# STM32L4x6_v1r1 register map
File version: 1.1
CPU: CM4 r0p1, little endian, MPU, FPU, 4 interrupt priority bits
Registers are 32-bit, read-write, reset 0x0 unless marked. A register's access mark holds for its fields unless they carry their own. Offsets are from the block's base; [hi:lo] are bit positions; {n}, {i} and the like mark numbered series.

## ADC_Common — Analog-to-Digital Converter
Base 0x50040300
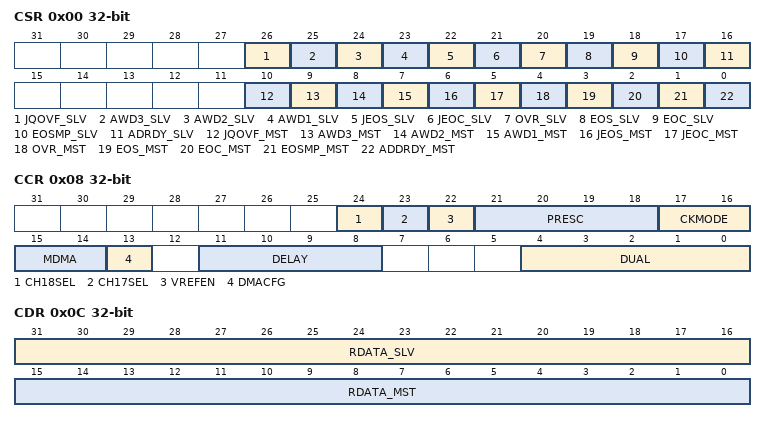
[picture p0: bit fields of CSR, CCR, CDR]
0x00 CSR ro — ADC Common status register
  [26] JQOVF_SLV — Injected Context Queue Overflow flag of the slave ADC
  [25] AWD3_SLV — Analog watchdog 3 flag of the slave ADC
  [24] AWD2_SLV — Analog watchdog 2 flag of the slave ADC
  [23] AWD1_SLV — Analog watchdog 1 flag of the slave ADC
  [22] JEOS_SLV — End of injected sequence flag of the slave ADC
  [21] JEOC_SLV — End of injected conversion flag of the slave ADC
  [20] OVR_SLV — Overrun flag of the slave ADC
  [19] EOS_SLV — End of regular sequence flag of the slave ADC
  [18] EOC_SLV — End of regular conversion of the slave ADC
  [17] EOSMP_SLV
  [16] ADRDY_SLV
  [10] JQOVF_MST
  [9] AWD3_MST
  [8] AWD2_MST
  [7] AWD1_MST
  [6] JEOS_MST
  [5] JEOC_MST
  [4] OVR_MST
  [3] EOS_MST
  [2] EOC_MST
  [1] EOSMP_MST
  [0] ADDRDY_MST
0x08 CCR — ADC common control register
  [24] CH18SEL — CH18 selection
  [23] CH17SEL — CH17 selection
  [22] VREFEN — VREFINT enable
  [21:18] PRESC — ADC prescaler
  [17:16] CKMODE — ADC clock mode
  [15:14] MDMA — Direct memory access mode for multi ADC mode
  [13] DMACFG — DMA configuration (for multi-ADC mode)
  [11:8] DELAY — Delay between 2 sampling phases
  [4:0] DUAL — Dual ADC mode selection
0x0C CDR ro — ADC common regular data register for dual and triple modes
  [31:16] RDATA_SLV — Regular data of the slave ADC
  [15:0] RDATA_MST — Regular data of the master ADC

## GPIOA — General-purpose I/Os
Base 0x48000000
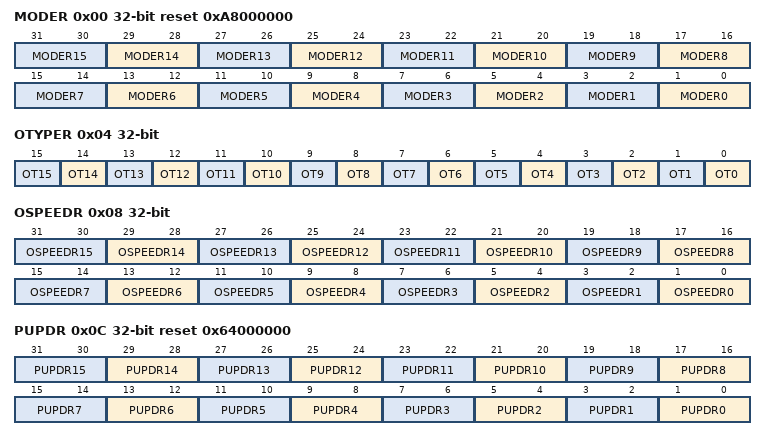
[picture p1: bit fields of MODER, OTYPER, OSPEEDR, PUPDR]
0x00 MODER reset 0xA8000000 — GPIO port mode register
  [2n+1:2n] MODER{n} (n=0..15) — Port x configuration bits (y = 0..15)
0x04 OTYPER — GPIO port output type register
  [n] OT{n} (n=0..15) — Port x configuration bits (y = 0..15)
0x08 OSPEEDR — GPIO port output speed register
  [2n+1:2n] OSPEEDR{n} (n=0..15) — Port x configuration bits (y = 0..15)
0x0C PUPDR reset 0x64000000 — GPIO port pull-up/pull-down register
  [2n+1:2n] PUPDR{n} (n=0..15) — Port x configuration bits (y = 0..15)
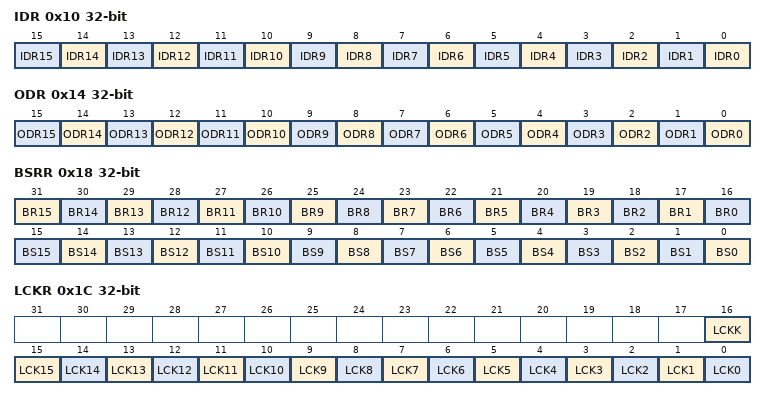
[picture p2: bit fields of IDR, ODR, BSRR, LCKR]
0x10 IDR ro — GPIO port input data register
  [n] IDR{n} (n=0..15) — Port input data (y = 0..15)
0x14 ODR — GPIO port output data register
  [n] ODR{n} (n=0..15) — Port output data (y = 0..15)
0x18 BSRR wo — GPIO port bit set/reset register
  [n+16] BR{n} (n=1..15) — Port x reset bit y (y = 0..15)
  [16] BR0 — Port x set bit y (y= 0..15)
  [n] BS{n} (n=0..15) — Port x set bit y (y= 0..15)
0x1C LCKR — GPIO port configuration lock register
  [16] LCKK — Port x lock bit y (y= 0..15)
  [n] LCK{n} (n=0..15) — Port x lock bit y (y= 0..15)
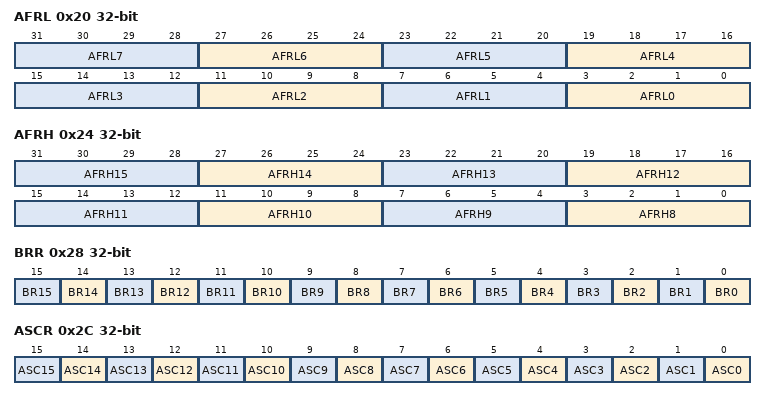
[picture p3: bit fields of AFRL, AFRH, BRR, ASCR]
0x20 AFRL — GPIO alternate function low register
  [4n+3:4n] AFRL{n} (n=0..7) — Alternate function selection for port x bit y (y = 0..7)
0x24 AFRH — GPIO alternate function high register
  [4n-29:4n-32] AFRH{n} (n=8..15) — Alternate function selection for port x bit y (y = 8..15)
0x28 BRR wo — GPIO port bit reset register
  [n] BR{n} (n=0..15) — Port Reset bit
0x2C ASCR — GPIO port analog switch control register
  [n] ASC{n} (n=0..15) — Port analog switch control

## GPIOB — General-purpose I/Os
Base 0x48000400
Registers as GPIOA; these are added or differ:
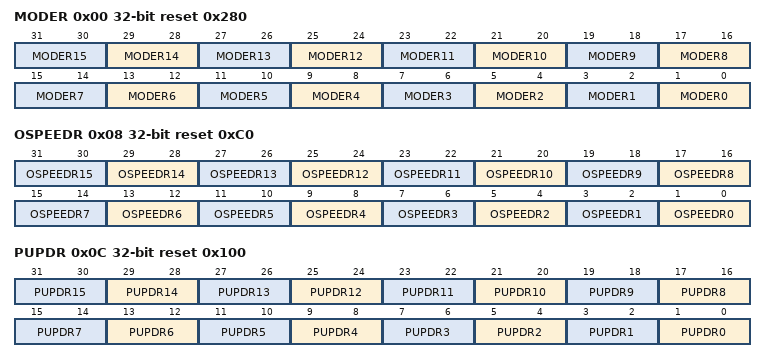
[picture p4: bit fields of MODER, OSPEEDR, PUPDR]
0x00 MODER reset 0x280 — GPIO port mode register
  [2n+1:2n] MODER{n} (n=0..15) — Port x configuration bits (y = 0..15)
0x08 OSPEEDR reset 0xC0 — GPIO port output speed register
  [2n+1:2n] OSPEEDR{n} (n=0..15) — Port x configuration bits (y = 0..15)
0x0C PUPDR reset 0x100 — GPIO port pull-up/pull-down register
  [2n+1:2n] PUPDR{n} (n=0..15) — Port x configuration bits (y = 0..15)

## GPIOC — General-purpose I/Os
Base 0x48000800
Same registers: GPIOD 0x48000C00, GPIOE 0x48001000, GPIOF 0x48001400, GPIOG 0x48001800, GPIOH 0x48001C00
Registers as GPIOA; these are added or differ:
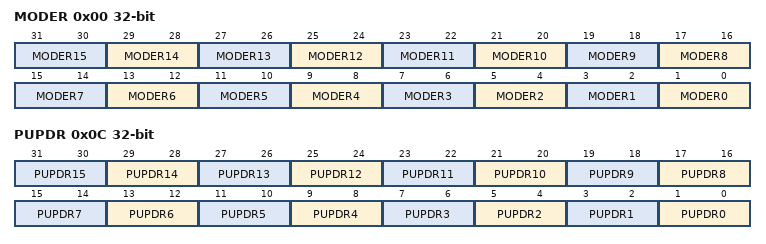
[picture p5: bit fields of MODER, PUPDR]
0x00 MODER — GPIO port mode register
  [2n+1:2n] MODER{n} (n=0..15) — Port x configuration bits (y = 0..15)
0x0C PUPDR — GPIO port pull-up/pull-down register
  [2n+1:2n] PUPDR{n} (n=0..15) — Port x configuration bits (y = 0..15)

## GPIOI — General-purpose I/Os
Base 0x48002000
Registers as GPIOC, without ASCR.
